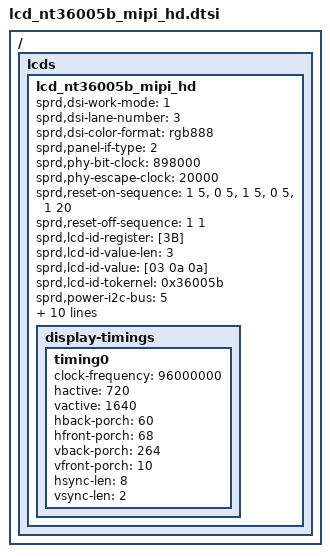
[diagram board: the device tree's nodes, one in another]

/*
 * NT36xxx  LCD config dtsi file for spreadtrum
 *
 * Copyright (C) 2018, Spreadtrum Communications Inc.
 *
 * SPDX-License-Identifier: (GPL-2.0+ OR MIT)
 */

/ { lcds {
  lcd_nt36005b_mipi_hd: lcd_nt36005b_mipi_hd {

	sprd,dsi-work-mode = <1>; /* video burst mode*/
	sprd,dsi-lane-number = <3>;
	sprd,dsi-color-format = "rgb888";
	sprd,panel-if-type = <2>;

	sprd,phy-bit-clock = <898000>;	/* kbps */
	sprd,phy-escape-clock = <20000>;/* kHz */

	sprd,reset-on-sequence = <1 5>, <0 5>, <1 5>, <0 5>, <1 20>;
	sprd,reset-off-sequence = <1 1>;

	sprd,lcd-id-register = [3B];
	sprd,lcd-id-value-len = <3>;
	sprd,lcd-id-value = [03 0a 0a];
	sprd,lcd-id-tokernel = <0x36005b>;

	/*---Bias Power---*/
	sprd,power-i2c-bus = <5>;
	sprd,power-i2c-addr = <0x3E>;
	sprd,power-i2c-speed = <100000>;
	sprd,power-i2c-reg = [00 01];
	sprd,power-i2c-val = [14 14];

	sprd,initial-command = [
		23 00 00 02 FF 20
		23 00 00 02 FB 01
		23 00 00 02 01 55
		23 00 00 02 03 55
		23 00 00 02 05 91
		23 00 00 02 07 4B
		23 00 00 02 08 CB
		23 00 00 02 0E 69
		23 00 00 02 0F 69
		23 00 00 02 94 C0
		23 00 00 02 95 09
		23 00 00 02 96 09
		23 00 00 02 69 91
		23 00 00 02 1F 02
		23 00 00 02 FF 20
		23 00 00 02 FB 01
		39 00 00 11 B0 00 08 00 09 00 2D 00 41 00 53 00 65 00 74 00 83
		39 00 00 11 B1 00 91 00 C5 00 ED 01 31 01 64 01 B8 01 F9 01 FC
		39 00 00 11 B2 02 3C 02 83 02 B3 02 EC 03 14 03 41 03 53 03 62
		39 00 00 0D B3 03 76 03 8C 03 A6 03 C0 03 CF 03 D1
		39 00 00 11 B4 00 08 00 09 00 2D 00 41 00 53 00 65 00 74 00 83
		39 00 00 11 B5 00 91 00 C5 00 ED 01 31 01 64 01 B8 01 F9 01 FC
		39 00 00 11 B6 02 3C 02 83 02 B3 02 EC 03 14 03 41 03 53 03 62
		39 00 00 0D B7 03 76 03 8C 03 A6 03 C0 03 CF 03 D1
		39 00 00 11 B8 00 08 00 09 00 2D 00 41 00 53 00 65 00 74 00 83
		39 00 00 11 B9 00 91 00 C5 00 ED 01 31 01 64 01 B8 01 F9 01 FC
		39 00 00 11 BA 02 3C 02 83 02 B3 02 EC 03 14 03 41 03 53 03 62
		39 00 00 0D BB 03 76 03 8C 03 A6 03 C0 03 CF 03 D1
		23 00 00 02 FF 21
		23 00 00 02 FB 01
		39 00 00 11 B0 00 00 00 01 00 25 00 39 00 4B 00 5D 00 6C 00 7B
		39 00 00 11 B1 00 89 00 BD 00 E5 01 29 01 5C 01 B0 01 F1 01 F4
		39 00 00 11 B2 02 34 02 7B 02 AB 02 E4 03 0C 03 39 03 4B 03 5A
		39 00 00 0D B3 03 6E 03 84 03 9E 03 B8 03 C7 03 C9
		39 00 00 11 B4 00 00 00 01 00 25 00 39 00 4B 00 5D 00 6C 00 7B
		39 00 00 11 B5 00 89 00 BD 00 E5 01 29 01 5C 01 B0 01 F1 01 F4
		39 00 00 11 B6 02 34 02 7B 02 AB 02 E4 03 0C 03 39 03 4B 03 5A
		39 00 00 0D B7 03 6E 03 84 03 9E 03 B8 03 C7 03 C9
		39 00 00 11 B8 00 00 00 01 00 25 00 39 00 4B 00 5D 00 6C 00 7B
		39 00 00 11 B9 00 89 00 BD 00 E5 01 29 01 5C 01 B0 01 F1 01 F4
		39 00 00 11 BA 02 34 02 7B 02 AB 02 E4 03 0C 03 39 03 4B 03 5A
		39 00 00 0D BB 03 6E 03 84 03 9E 03 B8 03 C7 03 C9
		23 00 00 02 FF 23
		23 00 00 02 FB 01
		23 00 00 02 12 B9
		23 00 00 02 15 E3
		23 00 00 02 16 0B
		23 00 00 02 FF 24
		23 00 00 02 FB 01
		23 00 00 02 93 0A
		23 00 00 02 94 12
		23 00 00 02 00 00
		23 00 00 02 01 1E
		23 00 00 02 02 1E
		23 00 00 02 03 1F
		23 00 00 02 04 1F
		23 00 00 02 05 1D
		23 00 00 02 06 1D
		23 00 00 02 07 06
		23 00 00 02 08 0C
		23 00 00 02 09 0C
		23 00 00 02 0A 0D
		23 00 00 02 0B 0D
		23 00 00 02 0C 0E
		23 00 00 02 0D 0E
		23 00 00 02 0E 0F
		23 00 00 02 0F 0F
		23 00 00 02 10 21
		23 00 00 02 11 21
		23 00 00 02 12 1C
		23 00 00 02 13 1C
		23 00 00 02 14 04
		23 00 00 02 15 05
		23 00 00 02 16 00
		23 00 00 02 17 1E
		23 00 00 02 18 1E
		23 00 00 02 19 1F
		23 00 00 02 1A 1F
		23 00 00 02 1B 1D
		23 00 00 02 1C 1D
		23 00 00 02 1D 07
		23 00 00 02 1E 0C
		23 00 00 02 1F 0C
		23 00 00 02 20 0D
		23 00 00 02 21 0D
		23 00 00 02 22 0E
		23 00 00 02 23 0E
		23 00 00 02 24 0F
		23 00 00 02 25 0F
		23 00 00 02 26 21
		23 00 00 02 27 21
		23 00 00 02 28 1C
		23 00 00 02 29 1C
		23 00 00 02 2A 04
		23 00 00 02 2B 05
		23 00 00 02 2D 0C
		23 00 00 02 41 44
		23 00 00 02 42 43
		23 00 00 02 45 43
		23 00 00 02 46 44
		23 00 00 02 47 44
		23 00 00 02 48 44
		23 00 00 02 49 00
		23 00 00 02 4A 24
		23 00 00 02 4B 91
		23 00 00 02 4C 54
		23 00 00 02 2F 0A
		23 00 00 02 30 08
		23 00 00 02 31 0E
		23 00 00 02 32 0F
		23 00 00 02 33 08
		23 00 00 02 34 0A
		23 00 00 02 35 0F
		23 00 00 02 36 0E
		23 00 00 02 37 44
		23 00 00 02 38 44
		23 00 00 02 39 00
		23 00 00 02 3A 65
		23 00 00 02 3B 8A
		23 00 00 02 3D 54
		23 00 00 02 4D 34
		23 00 00 02 4E 12
		23 00 00 02 4F 00
		23 00 00 02 50 00
		23 00 00 02 51 21
		23 00 00 02 52 43
		23 00 00 02 53 00
		23 00 00 02 54 00
		23 00 00 02 55 47
		23 00 00 02 56 44
		23 00 00 02 58 21
		23 00 00 02 59 00
		23 00 00 02 5A 65
		23 00 00 02 5B 8A
		23 00 00 02 5C 88
		23 00 00 02 5D 08
		23 00 00 02 5E 04
		23 00 00 02 5F 00
		23 00 00 02 60 80
		23 00 00 02 61 9A
		23 00 00 02 64 10
		23 00 00 02 80 0F
		23 00 00 02 81 09
		23 00 00 02 82 0F
		23 00 00 02 83 09
		23 00 00 02 84 80
		23 00 00 02 85 01
		23 00 00 02 86 04
		23 00 00 02 88 40
		23 00 00 02 89 C8
		23 00 00 02 8A 88
		23 00 00 02 8D 08
		23 00 00 02 8E 08
		23 00 00 02 91 40
		23 00 00 02 92 AE
		23 00 00 02 98 80
		23 00 00 02 AB 00
		23 00 00 02 AD 00
		23 00 00 02 AF 04
		23 00 00 02 B0 05
		23 00 00 02 B1 AA
		23 00 00 02 FF 25
		23 00 00 02 FB 01
		23 00 00 02 17 82
		23 00 00 02 18 06
		23 00 00 02 19 0F
		23 00 00 02 C0 07
		23 00 00 02 C2 84
		23 00 00 02 C6 92
		23 00 00 02 CA 1C
		23 00 00 02 CB 1C
		23 00 00 02 CC 1C
		23 00 00 02 CD 00
		23 00 00 02 CE 00
		23 00 00 02 D3 11
		23 00 00 02 D4 CC
		23 00 00 02 D5 11
		23 00 00 02 D6 1C
		23 00 00 02 D7 11
		23 00 00 02 0A 82
		23 00 00 02 0B 17
		23 00 00 02 0C 01
		23 00 00 02 FF 26
		23 00 00 02 FB 01
		23 00 00 02 00 A0
		23 00 00 02 FF 27
		23 00 00 02 FB 01
		23 00 00 02 13 00
		23 00 00 02 15 B4
		23 00 00 02 1F 55
		23 00 00 02 26 0F
		23 00 00 02 C0 18
		23 00 00 02 C1 F8
		23 00 00 02 C7 03
		23 00 00 02 C2 00
		23 00 00 02 C3 00
		23 00 00 02 C4 F8
		23 00 00 02 C5 00
		23 00 00 02 C6 00
		23 00 00 02 FF D0
		23 00 00 02 FB 01
		23 00 00 02 05 07
		23 00 00 02 09 F0
		23 00 00 02 28 70
		23 00 00 02 FF 10
		23 00 00 02 FB 01
		23 00 00 02 53 24
		23 00 00 02 55 01
		23 00 00 02 BA 02
		23 00 00 02 35 00
		23 78 00 02 11 00
		23 14 00 02 29 00
		];

		sprd,sleep-in-command = [
			13 14 00 01 28
			13 78 00 01 10
		];

		sprd,sleep-out-command = [
			13 78 00 01 11
			13 14 00 01 29
		];

		display-timings {
			timing0 {
				clock-frequency = <96000000>;
				hactive = <720>;
				vactive = <1640>;
				hback-porch = <60>;
				hfront-porch = <68>;
				vback-porch = <264>;
				vfront-porch = <10>;
				hsync-len = <8>;
				vsync-len = <2>;
			};
		};
	};
};};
